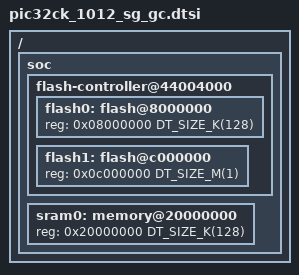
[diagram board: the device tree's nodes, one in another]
/*
 * Copyright (c) 2026 Microchip Technology Inc.
 *
 * SPDX-License-Identifier: Apache-2.0
 */
/ {
	soc {
		flash-controller@44004000 {
			flash0: flash@8000000 {
				reg = <0x08000000 DT_SIZE_K(128)>;
				ranges = <0x0 0x08000000 DT_SIZE_K(128)>;
			};

			flash1: flash@c000000 {
				reg = <0x0c000000 DT_SIZE_M(1)>;
				ranges = <0x0 0x0c000000 DT_SIZE_M(1)>;
			};
		};

		sram0: memory@20000000 {
			reg = <0x20000000 DT_SIZE_K(128)>;
		};
	};
};
